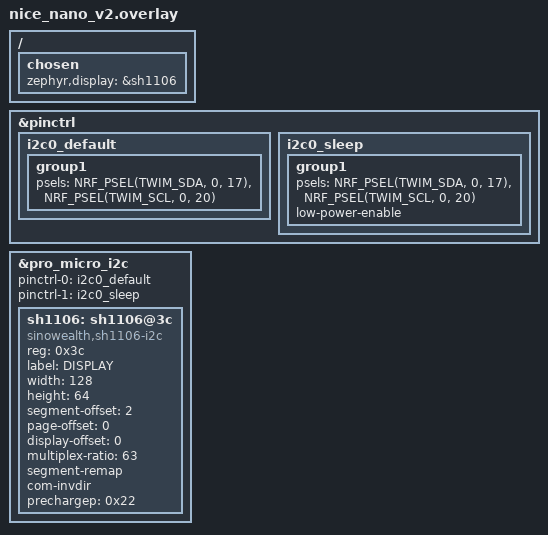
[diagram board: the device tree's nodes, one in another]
#include <dt-bindings/led/led.h>

&pinctrl {
    i2c0_default: i2c0_default {
        group1 {
            psels = <NRF_PSEL(TWIM_SDA, 0, 17)>,
                    <NRF_PSEL(TWIM_SCL, 0, 20)>;
        };
    };

    i2c0_sleep: i2c0_sleep {
        group1 {
            psels = <NRF_PSEL(TWIM_SDA, 0, 17)>,
                    <NRF_PSEL(TWIM_SCL, 0, 20)>;
            low-power-enable;
        };
    };
};

&pro_micro_i2c {
    status = "okay";
    pinctrl-0 = <&i2c0_default>;
    pinctrl-1 = <&i2c0_sleep>;
    pinctrl-names = "default", "sleep";

    sh1106: sh1106@3c {
        compatible = "sinowealth,sh1106-i2c";
        reg = <0x3c>;
        label = "DISPLAY";
        width = <128>;
        height = <64>;
        segment-offset = <2>;
        page-offset = <0>;
        display-offset = <0>;
        multiplex-ratio = <63>;
        segment-remap;
        com-invdir;
        prechargep = <0x22>;
    };
};

/ {
    chosen {
        zephyr,display = &sh1106;
    };
};
